# FM33FG0XXA register map
File version: 1.0
CPU: SC000 r1p0, little endian, MPU, no FPU, 3 interrupt priority bits
Registers are 32-bit, read-only, reset 0x0 unless marked. A register's access mark holds for its fields unless they carry their own. Offsets are from the block's base; [hi:lo] are bit positions; {n}, {i} and the like mark numbered series; 'fields as' and 'values as' point back to an identical list.

## TAU0 — TAU0 module information
Base 0x40015800
0x00 CR rw — TAU0 Control Register
  [7:0] TEN — TEN field description
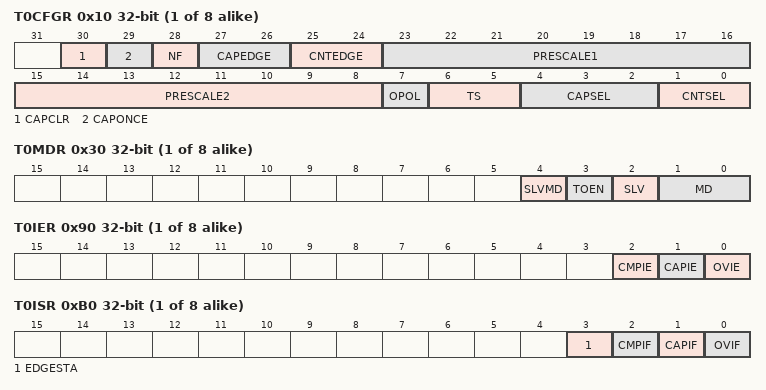
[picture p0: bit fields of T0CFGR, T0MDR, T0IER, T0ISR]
{0x10+4i} T{i}CFGR rw (i=0..7) — TAU0's Channel{i} Configuration Register
  [30] CAPCLR — CAPCLR field description
  [29] CAPONCE — CAPONCE field description
  [28] NF — NF field description
  [27:26] CAPEDGE — CAPEDGE field description
  [25:24] CNTEDGE — CNTEDGE field description
  [23:16] PRESCALE1 — PRESCALE1 field description
  [15:8] PRESCALE2 — PRESCALE2 field description
  [7] OPOL — OPOL field description
  [6:5] TS — TS field description
  [4:2] CAPSEL — CAPSEL field description
  [1:0] CNTSEL — CNTSEL field description
{0x30+4i} T{i}MDR rw (i=0..7) — TAU0's Channel{i} Mode Register
  [4] SLVMD — SLVMD field description
  [3] TOEN — TOEN field description
  [2] SLV — SLV field description
  [1:0] MD — MD field description
{0x50+4i} T{i}ARR rw (i=0..7) — TAU0 Auto-Reload Register{i}
  [15:0] ARR — ARR field description
{0x70+4i} T{i}CCR rw (i=0..7) — TAU0 Capture/Compare Register{i}
  [15:0] CCR — CCR field description
{0x90+4i} T{i}IER rw (i=0..7) — TAU0 Interrupt Enable Register{i}
  [2] CMPIE — CMPIE field description
  [1] CAPIE — CAPIE field description
  [0] OVIE — OVIE field description
{0xB0+4i} T{i}ISR rw (i=0..7) — TAU0 Interrupt Status Register{i}
  [3] EDGESTA — EDGESTA field description
  [2] CMPIF — CMPIF field description
  [1] CAPIF — CAPIF field description
  [0] OVIF — OVIF field description
{0xD0+4i} T{i}CNTR (i=0..7) — TAU0 Counter Register{i}
  [15:0] CNT — CNT field description

## TAU1 — TAU1 module information
Base 0x40015800
0x04 CR rw — TAU1 Control Register
  [7:0] TEN — TEN field description
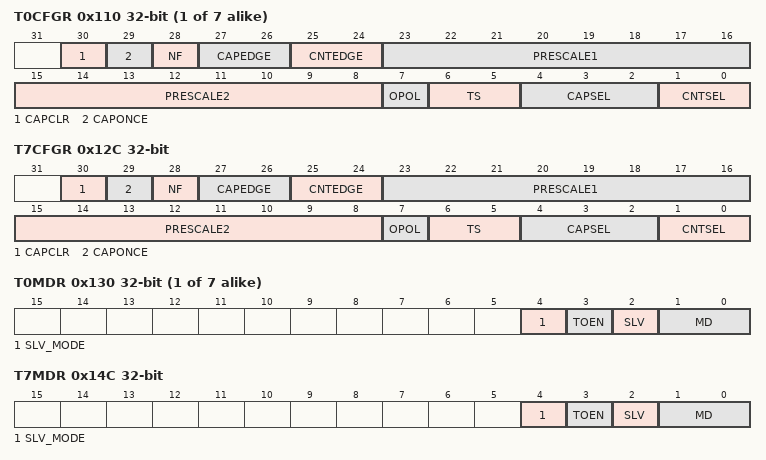
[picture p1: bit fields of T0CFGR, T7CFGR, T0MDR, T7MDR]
{0x110+4i} T{i}CFGR rw (i=0..6) — TAU1's Channel{i} Configuration Register
  [30] CAPCLR — CAPCLR field description
  [29] CAPONCE — CAPONCE field description
  [28] NF — NF field description
  [27:26] CAPEDGE — CAPEDGE field description
  [25:24] CNTEDGE — CNTEDGE field description
  [23:16] PRESCALE1 — PRESCALE1 field description
  [15:8] PRESCALE2 — PRESCALE2 field description
  [7] OPOL — OPOL field description
  [6:5] TS — TS field description
  [4:2] CAPSEL — CAPSEL field description
  [1:0] CNTSEL — CNTSEL field description
0x12C T7CFGR rw — TAU1's Channel3 Configuration Register
  fields as T0CFGR
{0x130+4i} T{i}MDR rw (i=0..6) — TAU1's Channel{i} Mode Register
  [4] SLV_MODE — SLV_MODE field description
  [3] TOEN — TOEN field description
  [2] SLV — SLV field description
  [1:0] MD — MD field description
0x14C T7MDR rw — TAU1's Channel3 Mode Register
  fields as T0MDR
{0x150+4i} T{i}ARR rw (i=0..7) — TAU1 Auto-Reload Register{i}
  [15:0] ARR — ARR field description
{0x170+4i} T{i}CCR rw (i=0..6) — TAU1 Capture/Compare Register{i}
  [15:0] CCR — CCR field description
0x18C T7CCR rw — TAU1 Capture/Compare Register3
  [15:0] CCR — CCR field description
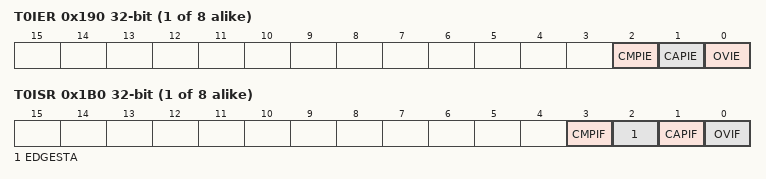
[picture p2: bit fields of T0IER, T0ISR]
{0x190+4i} T{i}IER rw (i=0..7) — TAU1 Interrupt Enable Register{i}
  [2] CMPIE — CMPIE field description
  [1] CAPIE — CAPIE field description
  [0] OVIE — OVIE field description
{0x1B0+4i} T{i}ISR rw (i=0..7) — TAU1 Interrupt Status Register{i}
  [3] CMPIF — CMPIF field description
  [2] EDGESTA — EDGESTA field description
  [1] CAPIF — CAPIF field description
  [0] OVIF — OVIF field description
{0x1D0+4i} T{i}CNTR (i=0..7) — TAU1 Counter Register{i}
  [15:0] CNT — CNT field description

## BSTIM32 — BSTIM32 module information
Base 0x40016000
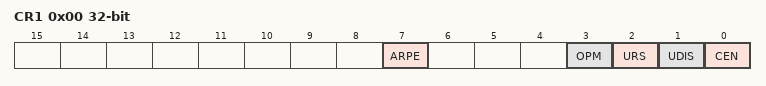
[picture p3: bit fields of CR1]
0x00 CR1 rw — BSTIM32 Control Register1
  [7] ARPE — ARPE field description
  [3] OPM — OPM field description
  [2] URS — URS field description
  [1] UDIS — UDIS field description
  [0] CEN — CEN field description
0x04 CR2 rw — BSTIM32 Control Register2
  [6:4] MMS — MMS field description
0x0C IER rw — BSTIM 32Interrupt Enable Register
  [0] UIE — UIE field description
0x10 ISR rw — BSTIM32 Interrupt Status Register
  [0] UIF — UIF field description
0x14 EGR wo — BSTIM32 Event Generation Register
  [0] UG — UG field description
0x24 CNT rw — BSTIM32 Counter Register
  [31:0] CNT — CNT field description
0x28 PSC rw — BSTIM32 Prescaler Register
  [31:0] PSC — PSC field description
0x2C ARR rw — BSTIM32 Auto-Reload Register
  [31:0] ARR — ARR field description

## BSTIM16 — BSTIM16 module information
Base 0x40018400
Registers as BSTIM32 (with BSTIM32 read as BSTIM16); these are added or differ:
0x0C IER rw — BSTIM16 Interrupt Enable Register
  [0] UIE — UIE field description
0x24 CNT rw — BSTIM16 Counter Register
  [15:0] CNT — CNT field description
0x28 PSC rw — BSTIM16 Prescaler Register
  [15:0] PSC — PSC field description
0x2C ARR rw reset 0xFFFF — BSTIM16 Auto-Reload Register
  [15:0] ARR — ARR field description
